VERSION ""

NS_ :

BS_:

BU_: XXX

BO_ 928 EPB_STATUS: 8 XXX
 SG_ EPB_BRAKE : 16|1@1+ (1,0) [0|3] "" XXX

BO_ 1104 SEATBELT_STATUS: 8 XXX
 SG_ DRIVER_SEAT_BELT_ONOFF : 21|1@0+ (1,0) [0|3] "" XXX

BO_ 1056 WINDOWS_TURNLED_STATUS: 8 XXX

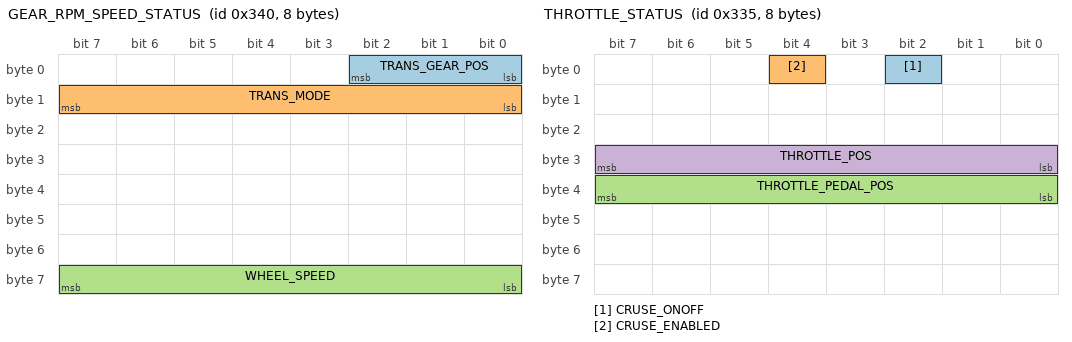
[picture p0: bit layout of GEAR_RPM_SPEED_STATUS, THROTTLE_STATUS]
BO_ 832 GEAR_RPM_SPEED_STATUS: 8 XXX
 SG_ TRANS_GEAR_POS : 0|3@1+ (1,0) [0|1] "" XXX
 SG_ TRANS_MODE : 8|8@1+ (1,0) [0|0] "" XXX
 SG_ WHEEL_SPEED : 63|8@0+ (1,0) [0|255] "KM" XXX

BO_ 821 THROTTLE_STATUS: 8 XXX
 SG_ CRUSE_ONOFF : 2|1@0+ (1,0) [0|1] "on/off" XXX
 SG_ CRUSE_ENABLED : 4|1@0+ (1,0) [0|1] "" XXX
 SG_ THROTTLE_PEDAL_POS : 32|8@1+ (1,0) [0|255] "" XXX
 SG_ THROTTLE_POS : 24|8@1+ (1,0) [0|255] "" XXX

BO_ 922 STEERING_ANGLE_STATUS: 8 XXX

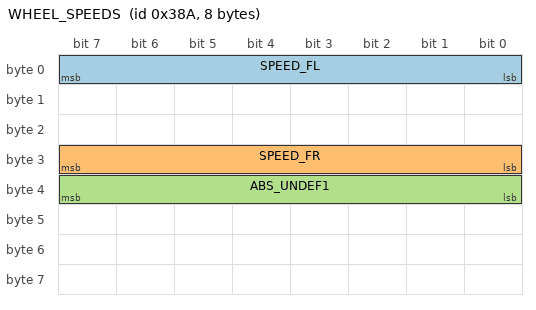
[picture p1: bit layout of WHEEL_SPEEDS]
BO_ 906 WHEEL_SPEEDS: 8 XXX
 SG_ SPEED_FL : 0|8@1+ (1,0) [0|255] "" XXX
 SG_ SPEED_FR : 24|8@1+ (1,0) [0|255] "" XXX
 SG_ ABS_UNDEF1 : 32|8@1+ (1,0) [0|255] "" XXX

CM_ SG_ 1104 DRIVER_SEAT_BELT_ONOFF "0 - on , 1 = off";
CM_ SG_ 832 TRANS_MODE "AT - 85 / MT - 8D";
CM_ SG_ 821 CRUSE_ONOFF "定速開關（但未啟動)";
CM_ SG_ 821 CRUSE_ENABLED "定速巡航啟動";
CM_ SG_ 821 THROTTLE_PEDAL_POS "踏板真實油門";
CM_ SG_ 821 THROTTLE_POS "巡航定速會用的油門";
CM_ SG_ 906 ABS_UNDEF1 "ABS force";
